# ATA5791 device description
Architecture: AVR8; Family: megaAVR
Programming and debug interfaces: ISP, HVPP, debugWIRE
Registers are 8-bit, access not given, no defined reset value unless marked. A register's access mark holds for its fields unless they carry their own. Offsets are from the block's base; lines under a group give offsets from that group; [hi:lo] are bit positions; {n}, {i} and the like mark numbered series; 'fields as' and 'values as' point back to an identical list; <NAME> marks a mode.

## Ordering variants
standard: 1.9 to 3.6 V

## Memory
prog space: start 0x0000 size 0x4000, little endian
  0x0000 FLASH size 0x4000 flash, rw, executable, page 0x80
  0x3800 BOOT_SECTION_1 size 0x0800 flash, rw, executable, page 0x80
signatures space: start 0 size 3, little endian
  0 SIGNATURES size 3 signatures, ro
fuses space: start 0 size 0x0001, little endian
  0 FUSES size 0x0001 fuses, rw
lockbits space: start 0 size 0x0001, little endian
  0 LOCKBITS size 0x0001 lockbits, rw
data space: start 0x0000 size 0x0300, little endian
  0x0000 REGISTERS size 0x0020 regs
  0x0020 MAPPED_IO size 0x00e0 io
  0x0100 IRAM size 0x0200 ram
eeprom space: start 0x0000 size 0x0800, little endian
  0x0000 EEPROM size 0x0800 eeprom, rw, page 0x10
io space: start 0x00 size 0x40, little endian

## Peripheral instances (address, pins/pin function, parameters)
SPI at 0x00
CPU at 0x00
  parameters: CORE_VERSION=V2E
AFE at 0x00
DDDLFRX at 0x00
IRLED at 0x00
AES at 0x00
MOD at 0x00
VMON at 0x00
EXTERNAL_INTERRUPT at 0x00
EEPROM at 0x00
PORTB at 0x00
PORTD at 0x00
TIMER_COUNTER_0 at 0x00
TIMER_COUNTER_1 at 0x00
TIMER_COUNTER_2 at 0x00
TIMER_COUNTER_3 at 0x00
RTC_TIMER at 0x00
WDT at 0x00 — Watchdog Timer
CRC at 0x00
PORTC at 0x00
FUSE at 0 in fuses
LOCKBIT at 0 in lockbits

## Interrupts
0 RESET — External Pin, Power-on Reset, Brown-out Reset, Watchdog Reset and Transponder Reset
1 TPINT — Transponder Mode Interrupt
2 INT0 — External Interrupt Request 0
3 PCINT0 — Pin Change Interrupt Request 0
4 PCINT1 — Pin Change Interrupt Request 1
5 VMINT — Voltage Monitoring Interrupt
6 T0INT — Timer0 Interval Interrupt
7 LFID0INT — LF-Receiver Identifier 0 Interrupt
8 LFID1INT — LF-Receiver Identifier 1 Interrupt
9 LFFEINT — LF-Receiver Frame End Interrupt
10 LFDBINT — LF-Receiver Data Buffer full Interrupt
11 T3CAPINT — Timer/Counter3 Capture Event Interrupt
12 T3COMINT — Timer/Counter3 Compare Match Interrupt
13 T3OVFINT — Timer/Counter3 Overflow Interrupt
14 T3COM2INT — Timer/Counter3 Compare Match 2 Interrupt
15 T2COMINT — Timer/Counter2 Compare Match Interrupt
16 T2OVFINT — Timer/Counter2 Overflow Interrupt
17 T1INT — Timer 1 Interval Interrupt
18 SPISTC — SPI Serial Transfer Complete Interrupt
19 TMRXBINT — Timer Modulator SSI Receive Buffer Interrupt
20 TMTXBINT — Timer Modulator SSI Transmit Buffer Interrupt
21 TMTXCINT — Timer Modulator Transmit Complete Interrupt
22 AESINT — AES Interrupt
23 LFRSSINT — LF-Receiver RSSi measurement Interrupt
24 LFSDINT — LF-Receiver Signal Detect Interrupt
25 LFMDINT — LF-Receiver Manchester Decoder error Interrupt
26 EXCMINT — External Input Clock Monitoring Interrupt
27 EXXMINT — External XTAL Oscillator Break Down Interrupt
28 RTCINT — Real Time Clock Interrupt
29 EEREADY — EEPROM Ready Interrupt
30 SPMREADY — Store Program Memory Ready

## Properties
SIGNATURES: JTAGID=0x9462, SIGNATURE0=0x1e, SIGNATURE1=0x94, SIGNATURE2=0x62
OCD: OCD_REVISION=1, OCD_DATAREG=0x31, PROGBASE=0x0000

## FUSE
Instances: FUSE 0 in fuses
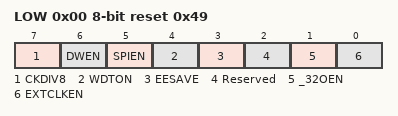
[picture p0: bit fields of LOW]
0x00 LOW reset 0x49
  [7] CKDIV8 — Divide clock by 8 internally
  [6] DWEN — DebugWIRE Enable
  [5] SPIEN — SPI Enable
  [4] WDTON — Enable Watchdog Timer
  [3] EESAVE — Preserve EEPROM through the Chip Erase cycle
  [2] Reserved — This fuse bit must be set.
  [1] _32OEN — Enables the 32 kHz oscillator.
  [0] EXTCLKEN — External Clock enable

## LOCKBIT
Instances: LOCKBIT 0 in lockbits
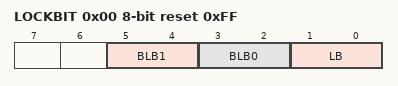
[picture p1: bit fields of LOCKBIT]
0x00 LOCKBIT reset 0xFF
  [5:4] BLB1 — Boot Loader Protection Mode
    0=LPM_AND_SPM_PROHIBITED_IN_BOOT_SECTION; 1=LPM_PROHIBITED_IN_BOOT_SECTION; 2=SPM_PROHIBITED_IN_BOOT_SECTION; 3=NO_LOCK_ON_SPM_AND_LPM_IN_BOOT_SECTION
  [3:2] BLB0 — Boot Loader Protection Mode
    0=LPM_AND_SPM_PROHIBITED_IN_APPLICATION_SECTION; 1=LPM_PROHIBITED_IN_APPLICATION_SECTION; 2=SPM_PROHIBITED_IN_APPLICATION_SECTION; 3=NO_LOCK_ON_SPM_AND_LPM_IN_APPLICATION_SECTION
  [1:0] LB — Memory Lock
    0=PROG_VER_DISABLED (Further programming and verification disabled); 2=PROG_DISABLED (Further programming disabled); 3=NO_LOCK (No memory lock features enabled)
